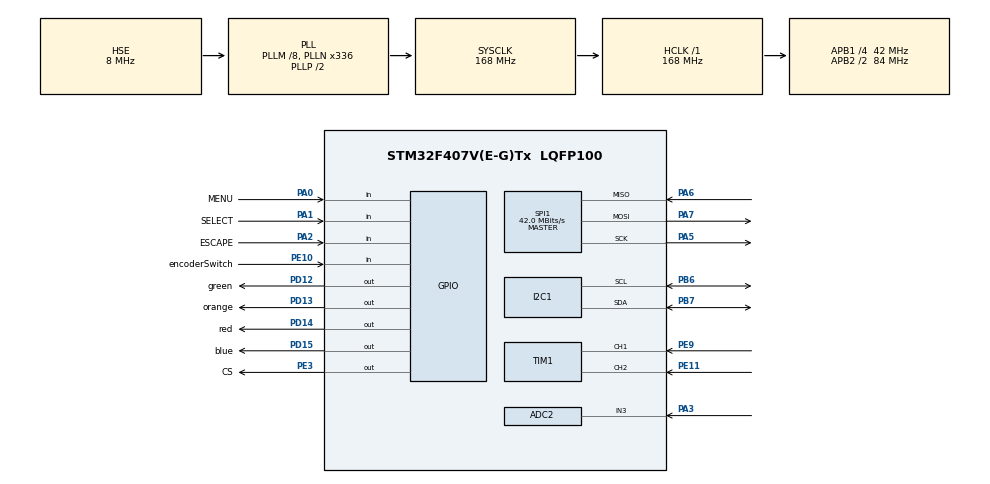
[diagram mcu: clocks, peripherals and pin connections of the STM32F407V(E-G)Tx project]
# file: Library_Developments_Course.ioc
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ADC2.Channel-0\#ChannelRegularConversion=ADC_CHANNEL_3
ADC2.NbrOfConversionFlag=1
ADC2.Rank-0\#ChannelRegularConversion=1
ADC2.SamplingTime-0\#ChannelRegularConversion=ADC_SAMPLETIME_3CYCLES
Mcu.Family=STM32F4
Mcu.Name=STM32F407V(E-G)Tx
Mcu.Package=LQFP100
NVIC.PriorityGroup=NVIC_PRIORITYGROUP_0
PA0-WKUP.GPIO_Label=MENU
PA0-WKUP.GPIO_PuPd=GPIO_PULLDOWN
PA0-WKUP.Signal=GPIO_Input
PA1.GPIO_Label=SELECT
PA1.GPIO_PuPd=GPIO_PULLDOWN
PA1.Signal=GPIO_Input
PA13.Mode=Serial_Wire
PA13.Signal=SYS_JTMS-SWDIO
PA14.Mode=Serial_Wire
PA14.Signal=SYS_JTCK-SWCLK
PA2.GPIO_Label=ESCAPE
PA2.GPIO_PuPd=GPIO_PULLDOWN
PA2.Signal=GPIO_Input
PA3.Signal=ADCx_IN3
PA5.Mode=Full_Duplex_Master
PA5.Signal=SPI1_SCK
PA6.Mode=Full_Duplex_Master
PA6.Signal=SPI1_MISO
PA7.Mode=Full_Duplex_Master
PA7.Signal=SPI1_MOSI
PB6.Mode=I2C
PB6.Signal=I2C1_SCL
PB7.Mode=I2C
PB7.Signal=I2C1_SDA
PD12.GPIO_Label=green
PD12.GPIO_Speed=GPIO_SPEED_FREQ_MEDIUM
PD12.Signal=GPIO_Output
PD13.GPIO_Label=orange
PD13.GPIO_Speed=GPIO_SPEED_FREQ_MEDIUM
PD13.Signal=GPIO_Output
PD14.GPIO_Label=red
PD14.GPIO_Speed=GPIO_SPEED_FREQ_MEDIUM
PD14.Signal=GPIO_Output
PD15.GPIO_Label=blue
PD15.GPIO_Speed=GPIO_SPEED_FREQ_MEDIUM
PD15.Signal=GPIO_Output
PE10.GPIO_Label=encoderSwitch
PE10.GPIO_PuPd=GPIO_PULLUP
PE10.Signal=GPIO_Input
PE11.Signal=S_TIM1_CH2
PE3.GPIO_Label=CS
PE3.GPIO_Speed=GPIO_SPEED_FREQ_MEDIUM
PE3.PinState=GPIO_PIN_SET
PE3.Signal=GPIO_Output
PE9.Signal=S_TIM1_CH1
PH0-OSC_IN.Mode=HSE-External-Oscillator
PH0-OSC_IN.Signal=RCC_OSC_IN
PH1-OSC_OUT.Mode=HSE-External-Oscillator
PH1-OSC_OUT.Signal=RCC_OSC_OUT
ProjectManager.HeapSize=0x200
ProjectManager.StackSize=0x400
ProjectManager.TargetToolchain=STM32CubeIDE
RCC.48MHZClocksFreq_Value=48000000
RCC.AHBFreq_Value=168000000
RCC.APB1CLKDivider=RCC_HCLK_DIV4
RCC.APB1Freq_Value=42000000
RCC.APB1TimFreq_Value=84000000
RCC.APB2CLKDivider=RCC_HCLK_DIV2
RCC.APB2Freq_Value=84000000
RCC.APB2TimFreq_Value=168000000
RCC.CortexFreq_Value=168000000
RCC.HCLKFreq_Value=168000000
RCC.HSE_VALUE=8000000
RCC.HSI_VALUE=16000000
RCC.LSE_VALUE=32768
RCC.PLLM=8
RCC.PLLN=336
RCC.PLLQ=7
RCC.PLLSourceVirtual=RCC_PLLSOURCE_HSE
RCC.SYSCLKFreq_VALUE=168000000
RCC.SYSCLKSource=RCC_SYSCLKSOURCE_PLLCLK
RCC.VCOOutputFreq_Value=336000000
SH.ADCx_IN3.0=ADC2_IN3,IN3
SH.S_TIM1_CH1.0=TIM1_CH1,Encoder_Interface
SH.S_TIM1_CH2.0=TIM1_CH2,Encoder_Interface
SPI1.CalculateBaudRate=42.0 MBits/s
SPI1.Direction=SPI_DIRECTION_2LINES
SPI1.Mode=SPI_MODE_MASTER
SPI1.VirtualType=VM_MASTER
TIM1.AutoReloadPreload=TIM_AUTORELOAD_PRELOAD_ENABLE
TIM1.EncoderMode=TIM_ENCODERMODE_TI12
TIM1.IC1Filter=10
TIM1.IC2Filter=10
board=STM32F407G-DISC1

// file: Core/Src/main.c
/* USER CODE BEGIN Header */
/**
 ******************************************************************************
 * @file           : main.c
 * @brief          : Main program body
 ******************************************************************************
 * @attention
 *
 * Copyright (c) 2024 STMicroelectronics.
 * All rights reserved.
 *
 * This software is licensed under terms that can be found in the LICENSE file
 * in the root directory of this software component.
 * If no LICENSE file comes with this software, it is provided AS-IS.
 *
 ******************************************************************************
 */
/* USER CODE END Header */
#include "main.h"

/* USER CODE BEGIN Includes */

#include "at24c256.h"
/* USER CODE END Includes */

ADC_HandleTypeDef hadc2;

I2C_HandleTypeDef hi2c1;

SPI_HandleTypeDef hspi1;

TIM_HandleTypeDef htim1;

/* USER CODE BEGIN PV */

uint8_t writeMessage[] = "arif mandal";
uint8_t readMessage[100] = { 0 };

/* USER CODE END PV */

void SystemClock_Config(void);
static void MX_GPIO_Init(void);
static void MX_I2C1_Init(void);
static void MX_SPI1_Init(void);
static void MX_ADC2_Init(void);
static void MX_TIM1_Init(void);

int main(void) {

	/* MCU Configuration--------------------------------------------------------*/

	/* Reset of all peripherals, Initializes the Flash interface and the Systick. */
	HAL_Init();

	/* Configure the system clock */
	SystemClock_Config();

	/* Initialize all configured peripherals */
	MX_GPIO_Init();
	MX_I2C1_Init();
	MX_SPI1_Init();
	MX_ADC2_Init();
	MX_TIM1_Init();
	/* USER CODE BEGIN 2 */

	AT24C256InitStatus ret = AT24C256_Init(&hi2c1);

	if (ret == INIT_SUCCESS) {
		AT24C256_Write(&hi2c1, 0, writeMessage, sizeof(writeMessage));
		AT24C256_Read(&hi2c1, 0, readMessage, sizeof(readMessage));
		AT24C256_Erase(&hi2c1);
		AT24C256_Read(&hi2c1, 0, readMessage, sizeof(readMessage));
	}

	/* USER CODE END 2 */

	/* Infinite loop */
	while (1) {

	}
}

void SystemClock_Config(void) {
	RCC_OscInitTypeDef RCC_OscInitStruct = { 0 };
	RCC_ClkInitTypeDef RCC_ClkInitStruct = { 0 };

	/** Configure the main internal regulator output voltage
	 */
	__HAL_RCC_PWR_CLK_ENABLE();
	__HAL_PWR_VOLTAGESCALING_CONFIG(PWR_REGULATOR_VOLTAGE_SCALE1);

	/** Initializes the RCC Oscillators according to the specified parameters
	 * in the RCC_OscInitTypeDef structure.
	 */
	RCC_OscInitStruct.OscillatorType = RCC_OSCILLATORTYPE_HSE;
	RCC_OscInitStruct.HSEState = RCC_HSE_ON;
	RCC_OscInitStruct.PLL.PLLState = RCC_PLL_ON;
	RCC_OscInitStruct.PLL.PLLSource = RCC_PLLSOURCE_HSE;
	RCC_OscInitStruct.PLL.PLLM = 8;
	RCC_OscInitStruct.PLL.PLLN = 336;
	RCC_OscInitStruct.PLL.PLLP = RCC_PLLP_DIV2;
	RCC_OscInitStruct.PLL.PLLQ = 7;
	if (HAL_RCC_OscConfig(&RCC_OscInitStruct) != HAL_OK) {
		Error_Handler();
	}

	/** Initializes the CPU, AHB and APB buses clocks
	 */
	RCC_ClkInitStruct.ClockType = RCC_CLOCKTYPE_HCLK | RCC_CLOCKTYPE_SYSCLK
			| RCC_CLOCKTYPE_PCLK1 | RCC_CLOCKTYPE_PCLK2;
	RCC_ClkInitStruct.SYSCLKSource = RCC_SYSCLKSOURCE_PLLCLK;
	RCC_ClkInitStruct.AHBCLKDivider = RCC_SYSCLK_DIV1;
	RCC_ClkInitStruct.APB1CLKDivider = RCC_HCLK_DIV4;
	RCC_ClkInitStruct.APB2CLKDivider = RCC_HCLK_DIV2;

	if (HAL_RCC_ClockConfig(&RCC_ClkInitStruct, FLASH_LATENCY_5) != HAL_OK) {
		Error_Handler();
	}
}

static void MX_ADC2_Init(void) {

	ADC_ChannelConfTypeDef sConfig = { 0 };

	/** Configure the global features of the ADC (Clock, Resolution, Data Alignment and number of conversion)
	 */
	hadc2.Instance = ADC2;
	hadc2.Init.ClockPrescaler = ADC_CLOCK_SYNC_PCLK_DIV4;
	hadc2.Init.Resolution = ADC_RESOLUTION_12B;
	hadc2.Init.ScanConvMode = DISABLE;
	hadc2.Init.ContinuousConvMode = DISABLE;
	hadc2.Init.DiscontinuousConvMode = DISABLE;
	hadc2.Init.ExternalTrigConvEdge = ADC_EXTERNALTRIGCONVEDGE_NONE;
	hadc2.Init.ExternalTrigConv = ADC_SOFTWARE_START;
	hadc2.Init.DataAlign = ADC_DATAALIGN_RIGHT;
	hadc2.Init.NbrOfConversion = 1;
	hadc2.Init.DMAContinuousRequests = DISABLE;
	hadc2.Init.EOCSelection = ADC_EOC_SINGLE_CONV;
	if (HAL_ADC_Init(&hadc2) != HAL_OK) {
		Error_Handler();
	}

	/** Configure for the selected ADC regular channel its corresponding rank in the sequencer and its sample time.
	 */
	sConfig.Channel = ADC_CHANNEL_3;
	sConfig.Rank = 1;
	sConfig.SamplingTime = ADC_SAMPLETIME_3CYCLES;
	if (HAL_ADC_ConfigChannel(&hadc2, &sConfig) != HAL_OK) {
		Error_Handler();
	}

}

static void MX_I2C1_Init(void) {

	hi2c1.Instance = I2C1;
	hi2c1.Init.ClockSpeed = 100000;
	hi2c1.Init.DutyCycle = I2C_DUTYCYCLE_2;
	hi2c1.Init.OwnAddress1 = 0;
	hi2c1.Init.AddressingMode = I2C_ADDRESSINGMODE_7BIT;
	hi2c1.Init.DualAddressMode = I2C_DUALADDRESS_DISABLE;
	hi2c1.Init.OwnAddress2 = 0;
	hi2c1.Init.GeneralCallMode = I2C_GENERALCALL_DISABLE;
	hi2c1.Init.NoStretchMode = I2C_NOSTRETCH_DISABLE;
	if (HAL_I2C_Init(&hi2c1) != HAL_OK) {
		Error_Handler();
	}

}

static void MX_SPI1_Init(void) {

	/* SPI1 parameter configuration*/
	hspi1.Instance = SPI1;
	hspi1.Init.Mode = SPI_MODE_MASTER;
	hspi1.Init.Direction = SPI_DIRECTION_2LINES;
	hspi1.Init.DataSize = SPI_DATASIZE_8BIT;
	hspi1.Init.CLKPolarity = SPI_POLARITY_LOW;
	hspi1.Init.CLKPhase = SPI_PHASE_1EDGE;
	hspi1.Init.NSS = SPI_NSS_SOFT;
	hspi1.Init.BaudRatePrescaler = SPI_BAUDRATEPRESCALER_2;
	hspi1.Init.FirstBit = SPI_FIRSTBIT_MSB;
	hspi1.Init.TIMode = SPI_TIMODE_DISABLE;
	hspi1.Init.CRCCalculation = SPI_CRCCALCULATION_DISABLE;
	hspi1.Init.CRCPolynomial = 10;
	if (HAL_SPI_Init(&hspi1) != HAL_OK) {
		Error_Handler();
	}

}

static void MX_TIM1_Init(void) {

	TIM_Encoder_InitTypeDef sConfig = { 0 };
	TIM_MasterConfigTypeDef sMasterConfig = { 0 };

	htim1.Instance = TIM1;
	htim1.Init.Prescaler = 0;
	htim1.Init.CounterMode = TIM_COUNTERMODE_UP;
	htim1.Init.Period = 65535;
	htim1.Init.ClockDivision = TIM_CLOCKDIVISION_DIV1;
	htim1.Init.RepetitionCounter = 0;
	htim1.Init.AutoReloadPreload = TIM_AUTORELOAD_PRELOAD_ENABLE;
	sConfig.EncoderMode = TIM_ENCODERMODE_TI12;
	sConfig.IC1Polarity = TIM_ICPOLARITY_RISING;
	sConfig.IC1Selection = TIM_ICSELECTION_DIRECTTI;
	sConfig.IC1Prescaler = TIM_ICPSC_DIV1;
	sConfig.IC1Filter = 10;
	sConfig.IC2Polarity = TIM_ICPOLARITY_RISING;
	sConfig.IC2Selection = TIM_ICSELECTION_DIRECTTI;
	sConfig.IC2Prescaler = TIM_ICPSC_DIV1;
	sConfig.IC2Filter = 10;
	if (HAL_TIM_Encoder_Init(&htim1, &sConfig) != HAL_OK) {
		Error_Handler();
	}
	sMasterConfig.MasterOutputTrigger = TIM_TRGO_RESET;
	sMasterConfig.MasterSlaveMode = TIM_MASTERSLAVEMODE_DISABLE;
	if (HAL_TIMEx_MasterConfigSynchronization(&htim1, &sMasterConfig)
			!= HAL_OK) {
		Error_Handler();
	}

}

static void MX_GPIO_Init(void) {
	GPIO_InitTypeDef GPIO_InitStruct = { 0 };

	/* GPIO Ports Clock Enable */
	__HAL_RCC_GPIOE_CLK_ENABLE();
	__HAL_RCC_GPIOH_CLK_ENABLE();
	__HAL_RCC_GPIOA_CLK_ENABLE();
	__HAL_RCC_GPIOD_CLK_ENABLE();
	__HAL_RCC_GPIOB_CLK_ENABLE();

	/*Configure GPIO pin Output Level */
	HAL_GPIO_WritePin(CS_GPIO_Port, CS_Pin, GPIO_PIN_SET);

	/*Configure GPIO pin Output Level */
	HAL_GPIO_WritePin(GPIOD, green_Pin | orange_Pin | red_Pin | blue_Pin,
			GPIO_PIN_RESET);

	/*Configure GPIO pin : CS_Pin */
	GPIO_InitStruct.Pin = CS_Pin;
	GPIO_InitStruct.Mode = GPIO_MODE_OUTPUT_PP;
	GPIO_InitStruct.Pull = GPIO_NOPULL;
	GPIO_InitStruct.Speed = GPIO_SPEED_FREQ_MEDIUM;
	HAL_GPIO_Init(CS_GPIO_Port, &GPIO_InitStruct);

	/*Configure GPIO pins : MENU_Pin SELECT_Pin ESCAPE_Pin */
	GPIO_InitStruct.Pin = MENU_Pin | SELECT_Pin | ESCAPE_Pin;
	GPIO_InitStruct.Mode = GPIO_MODE_INPUT;
	GPIO_InitStruct.Pull = GPIO_PULLDOWN;
	HAL_GPIO_Init(GPIOA, &GPIO_InitStruct);

	/*Configure GPIO pin : encoderSwitch_Pin */
	GPIO_InitStruct.Pin = encoderSwitch_Pin;
	GPIO_InitStruct.Mode = GPIO_MODE_INPUT;
	GPIO_InitStruct.Pull = GPIO_PULLUP;
	HAL_GPIO_Init(encoderSwitch_GPIO_Port, &GPIO_InitStruct);

	/*Configure GPIO pins : green_Pin orange_Pin red_Pin blue_Pin */
	GPIO_InitStruct.Pin = green_Pin | orange_Pin | red_Pin | blue_Pin;
	GPIO_InitStruct.Mode = GPIO_MODE_OUTPUT_PP;
	GPIO_InitStruct.Pull = GPIO_NOPULL;
	GPIO_InitStruct.Speed = GPIO_SPEED_FREQ_MEDIUM;
	HAL_GPIO_Init(GPIOD, &GPIO_InitStruct);

}

void Error_Handler(void) {
	__disable_irq();
	while (1) {
	}
}
